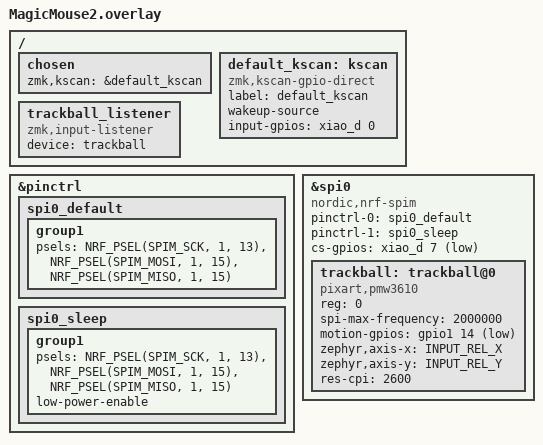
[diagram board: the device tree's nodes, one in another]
#include <zephyr/dt-bindings/input/input-event-codes.h>
#include <dt-bindings/zmk/input_transform.h>

/ {
        chosen {
            zmk,kscan = &default_kscan;
        };

        default_kscan: kscan {
            compatible = "zmk,kscan-gpio-direct";
            label = "default_kscan";
            wakeup-source;
            input-gpios =
                <&xiao_d 0 (GPIO_ACTIVE_HIGH | GPIO_PULL_UP)>;  
        };
};



                &pinctrl {
                    spi0_default: spi0_default {
                        group1 {
                            psels = <NRF_PSEL(SPIM_SCK, 1, 13)>,
                                <NRF_PSEL(SPIM_MOSI, 1, 15)>,
                                <NRF_PSEL(SPIM_MISO, 1, 15)>;
                        };
                    };
                
                    spi0_sleep: spi0_sleep {
                        group1 {
                            psels = <NRF_PSEL(SPIM_SCK, 1, 13)>, /*Sclk*/
                                <NRF_PSEL(SPIM_MOSI, 1, 15)>,
                                <NRF_PSEL(SPIM_MISO, 1, 15)>;/*SDIO*/
                            low-power-enable;
                        };
                    };
                };
    
        &spi0 {
            status = "okay";
            compatible = "nordic,nrf-spim";
            pinctrl-0 = <&spi0_default>;
            pinctrl-1 = <&spi0_sleep>;
            pinctrl-names = "default", "sleep";
            cs-gpios =  <&xiao_d 7 GPIO_ACTIVE_LOW>; /*NCS */
        
            trackball: trackball@0 {
                status = "okay";
                compatible = "pixart,pmw3610";
                reg = <0>;
                spi-max-frequency = <2000000>;
                motion-gpios = <&gpio1 14 (GPIO_ACTIVE_LOW | GPIO_PULL_UP)>; 
                zephyr,axis-x = <INPUT_REL_X>;
                zephyr,axis-y = <INPUT_REL_Y>;
                res-cpi = <2600>; 
        
                /*   optional features   */
                // snipe-layers = <1>;
                // scroll-layers = <2 3>;
                // automouse-layer = <4>;
            };
        };
        / {
            trackball_listener {

                compatible = "zmk,input-listener";
                status = "okay";
                device = <&trackball>;

            };
        };
